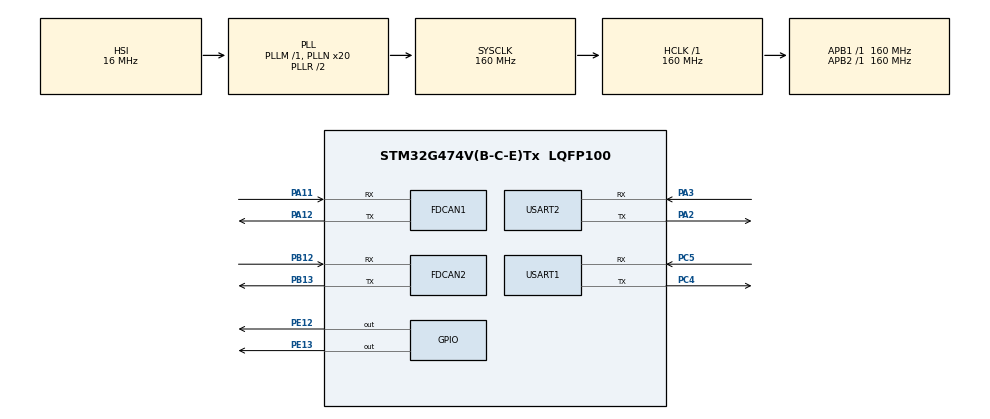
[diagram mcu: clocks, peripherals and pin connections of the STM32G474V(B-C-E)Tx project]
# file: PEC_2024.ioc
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Dma.Request0=USART2_RX
Dma.Request1=USART2_TX
Dma.Request2=USART1_RX
Dma.USART1_RX.2.Direction=DMA_PERIPH_TO_MEMORY
Dma.USART1_RX.2.EventEnable=DISABLE
Dma.USART1_RX.2.Instance=DMA1_Channel3
Dma.USART1_RX.2.MemDataAlignment=DMA_MDATAALIGN_BYTE
Dma.USART1_RX.2.MemInc=DMA_MINC_ENABLE
Dma.USART1_RX.2.Mode=DMA_NORMAL
Dma.USART1_RX.2.PeriphDataAlignment=DMA_PDATAALIGN_BYTE
Dma.USART1_RX.2.PeriphInc=DMA_PINC_DISABLE
Dma.USART1_RX.2.Polarity=HAL_DMAMUX_REQ_GEN_RISING
Dma.USART1_RX.2.Priority=DMA_PRIORITY_LOW
Dma.USART1_RX.2.RequestNumber=1
Dma.USART1_RX.2.SignalID=NONE
Dma.USART1_RX.2.SyncEnable=DISABLE
Dma.USART1_RX.2.SyncPolarity=HAL_DMAMUX_SYNC_NO_EVENT
Dma.USART1_RX.2.SyncRequestNumber=1
Dma.USART1_RX.2.SyncSignalID=NONE
Dma.USART2_RX.0.Direction=DMA_PERIPH_TO_MEMORY
Dma.USART2_RX.0.EventEnable=DISABLE
Dma.USART2_RX.0.Instance=DMA1_Channel1
Dma.USART2_RX.0.MemDataAlignment=DMA_MDATAALIGN_BYTE
Dma.USART2_RX.0.MemInc=DMA_MINC_ENABLE
Dma.USART2_RX.0.Mode=DMA_NORMAL
Dma.USART2_RX.0.PeriphDataAlignment=DMA_PDATAALIGN_BYTE
Dma.USART2_RX.0.PeriphInc=DMA_PINC_DISABLE
Dma.USART2_RX.0.Polarity=HAL_DMAMUX_REQ_GEN_RISING
Dma.USART2_RX.0.Priority=DMA_PRIORITY_LOW
Dma.USART2_RX.0.RequestNumber=1
Dma.USART2_RX.0.SignalID=NONE
Dma.USART2_RX.0.SyncEnable=DISABLE
Dma.USART2_RX.0.SyncPolarity=HAL_DMAMUX_SYNC_NO_EVENT
Dma.USART2_RX.0.SyncRequestNumber=1
Dma.USART2_RX.0.SyncSignalID=NONE
Dma.USART2_TX.1.Direction=DMA_MEMORY_TO_PERIPH
Dma.USART2_TX.1.EventEnable=DISABLE
Dma.USART2_TX.1.Instance=DMA1_Channel2
Dma.USART2_TX.1.MemDataAlignment=DMA_MDATAALIGN_BYTE
Dma.USART2_TX.1.MemInc=DMA_MINC_ENABLE
Dma.USART2_TX.1.Mode=DMA_NORMAL
Dma.USART2_TX.1.PeriphDataAlignment=DMA_PDATAALIGN_BYTE
Dma.USART2_TX.1.PeriphInc=DMA_PINC_DISABLE
Dma.USART2_TX.1.Polarity=HAL_DMAMUX_REQ_GEN_RISING
Dma.USART2_TX.1.Priority=DMA_PRIORITY_LOW
Dma.USART2_TX.1.RequestNumber=1
Dma.USART2_TX.1.SignalID=NONE
Dma.USART2_TX.1.SyncEnable=DISABLE
Dma.USART2_TX.1.SyncPolarity=HAL_DMAMUX_SYNC_NO_EVENT
Dma.USART2_TX.1.SyncRequestNumber=1
Dma.USART2_TX.1.SyncSignalID=NONE
FDCAN1.CalculateBaudRateNominal=1000000
FDCAN1.CalculateTimeBitNominal=1000
FDCAN1.CalculateTimeQuantumNominal=200.0
FDCAN1.NominalPrescaler=32
FDCAN2.CalculateBaudRateNominal=1000000
FDCAN2.CalculateTimeBitNominal=1000
FDCAN2.CalculateTimeQuantumNominal=200.0
FDCAN2.NominalPrescaler=32
FDCAN2.NominalTimeSeg1=2
FDCAN2.NominalTimeSeg2=2
Mcu.Family=STM32G4
Mcu.Name=STM32G474V(B-C-E)Tx
Mcu.Package=LQFP100
NVIC.DMA1_Channel1_IRQn=true\:0\:0\:false\:false\:true\:false\:true\:true
NVIC.DMA1_Channel2_IRQn=true\:0\:0\:false\:false\:true\:false\:true\:true
NVIC.DMA1_Channel3_IRQn=true\:0\:0\:false\:false\:true\:false\:true\:true
NVIC.FDCAN2_IT0_IRQn=true\:0\:0\:false\:false\:true\:true\:true\:true
NVIC.PriorityGroup=NVIC_PRIORITYGROUP_4
NVIC.USART1_IRQn=true\:0\:0\:false\:false\:true\:true\:true\:true
NVIC.USART2_IRQn=true\:0\:0\:false\:false\:true\:true\:true\:true
PA11.Mode=FDCAN_Activate
PA11.Signal=FDCAN1_RX
PA12.Mode=FDCAN_Activate
PA12.Signal=FDCAN1_TX
PA2.Mode=Asynchronous
PA2.Signal=USART2_TX
PA3.Mode=Asynchronous
PA3.Signal=USART2_RX
PB12.Mode=FDCAN_Activate
PB12.Signal=FDCAN2_RX
PB13.Mode=FDCAN_Activate
PB13.Signal=FDCAN2_TX
PC4.Mode=Asynchronous
PC4.Signal=USART1_TX
PC5.Mode=Asynchronous
PC5.Signal=USART1_RX
PE12.Signal=GPIO_Output
PE13.Signal=GPIO_Output
PF0-OSC_IN.Mode=HSE-External-Oscillator
PF0-OSC_IN.Signal=RCC_OSC_IN
PF1-OSC_OUT.Mode=HSE-External-Oscillator
PF1-OSC_OUT.Signal=RCC_OSC_OUT
ProjectManager.HeapSize=0x200
ProjectManager.StackSize=0x400
ProjectManager.TargetToolchain=STM32CubeIDE
RCC.ADC12Freq_Value=160000000
RCC.ADC345Freq_Value=160000000
RCC.AHBFreq_Value=160000000
RCC.APB1Freq_Value=160000000
RCC.APB1TimFreq_Value=160000000
RCC.APB2Freq_Value=160000000
RCC.APB2TimFreq_Value=160000000
RCC.CortexFreq_Value=160000000
RCC.EXTERNAL_CLOCK_VALUE=12288000
RCC.HCLKFreq_Value=160000000
RCC.HSE_VALUE=48000000
RCC.HSI48_VALUE=48000000
RCC.HSI_VALUE=16000000
RCC.LSE_VALUE=32768
RCC.PLLN=20
RCC.SYSCLKFreq_VALUE=160000000
RCC.SYSCLKSource=RCC_SYSCLKSOURCE_PLLCLK
RCC.USBFreq_Value=160000000
RCC.VCOOutputFreq_Value=320000000
USART1.VirtualMode-Asynchronous=VM_ASYNC
USART2.VirtualMode-Asynchronous=VM_ASYNC
VP_SYS_VS_DBSignals.Mode=DisableDeadBatterySignals
board=custom

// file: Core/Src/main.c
/* USER CODE BEGIN Header */
/**
  ******************************************************************************
  * @file           : main.c
  * @brief          : Main program body
  ******************************************************************************
  * @attention
  *
  * Copyright (c) 2024 STMicroelectronics.
  * All rights reserved.
  *
  * This software is licensed under terms that can be found in the LICENSE file
  * in the root directory of this software component.
  * If no LICENSE file comes with this software, it is provided AS-IS.
  *
  ******************************************************************************
  */
/* USER CODE END Header */
#include "main.h"
#include "dma.h"
#include "fdcan.h"
#include "usart.h"
#include "gpio.h"

/* USER CODE BEGIN Includes */
#include "fsm_main.h"
#include "retarget.h"
/* USER CODE END Includes */

/* USER CODE BEGIN PM */
extern uint8_t vision_buffer[256];
/* USER CODE END PM */

void SystemClock_Config(void);

int main(void)
{

  /* MCU Configuration--------------------------------------------------------*/

  /* Reset of all peripherals, Initializes the Flash interface and the Systick. */
  HAL_Init();

  /* Configure the system clock */
  SystemClock_Config();

  /* Initialize all configured peripherals */
  MX_GPIO_Init();
  MX_DMA_Init();
  MX_FDCAN1_Init();
  MX_USART1_UART_Init();
  MX_USART2_UART_Init();
  MX_FDCAN2_Init();
  /* USER CODE BEGIN 2 */
    init_fsm();
    RetargetInit(&huart1);
  /* USER CODE END 2 */

  /* Infinite loop */
  while (1)
  {

    /* USER CODE BEGIN 3 */
    //fsm_main();
    debug();
  }
  /* USER CODE END 3 */
}

void SystemClock_Config(void)
{
  RCC_OscInitTypeDef RCC_OscInitStruct = {0};
  RCC_ClkInitTypeDef RCC_ClkInitStruct = {0};

  /** Configure the main internal regulator output voltage
  */
  HAL_PWREx_ControlVoltageScaling(PWR_REGULATOR_VOLTAGE_SCALE1_BOOST);

  /** Initializes the RCC Oscillators according to the specified parameters
  * in the RCC_OscInitTypeDef structure.
  */
  RCC_OscInitStruct.OscillatorType = RCC_OSCILLATORTYPE_HSI;
  RCC_OscInitStruct.HSIState = RCC_HSI_ON;
  RCC_OscInitStruct.HSICalibrationValue = RCC_HSICALIBRATION_DEFAULT;
  RCC_OscInitStruct.PLL.PLLState = RCC_PLL_ON;
  RCC_OscInitStruct.PLL.PLLSource = RCC_PLLSOURCE_HSI;
  RCC_OscInitStruct.PLL.PLLM = RCC_PLLM_DIV1;
  RCC_OscInitStruct.PLL.PLLN = 20;
  RCC_OscInitStruct.PLL.PLLP = RCC_PLLP_DIV2;
  RCC_OscInitStruct.PLL.PLLQ = RCC_PLLQ_DIV2;
  RCC_OscInitStruct.PLL.PLLR = RCC_PLLR_DIV2;
  if (HAL_RCC_OscConfig(&RCC_OscInitStruct) != HAL_OK)
  {
    Error_Handler();
  }

  /** Initializes the CPU, AHB and APB buses clocks
  */
  RCC_ClkInitStruct.ClockType = RCC_CLOCKTYPE_HCLK|RCC_CLOCKTYPE_SYSCLK
                              |RCC_CLOCKTYPE_PCLK1|RCC_CLOCKTYPE_PCLK2;
  RCC_ClkInitStruct.SYSCLKSource = RCC_SYSCLKSOURCE_PLLCLK;
  RCC_ClkInitStruct.AHBCLKDivider = RCC_SYSCLK_DIV1;
  RCC_ClkInitStruct.APB1CLKDivider = RCC_HCLK_DIV1;
  RCC_ClkInitStruct.APB2CLKDivider = RCC_HCLK_DIV1;

  if (HAL_RCC_ClockConfig(&RCC_ClkInitStruct, FLASH_LATENCY_4) != HAL_OK)
  {
    Error_Handler();
  }
}

void Error_Handler(void)
{
  __disable_irq();
  while (1)
  {
  }
}
